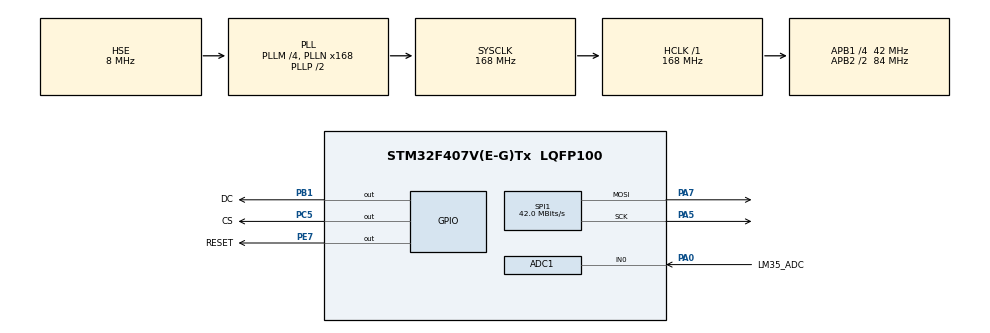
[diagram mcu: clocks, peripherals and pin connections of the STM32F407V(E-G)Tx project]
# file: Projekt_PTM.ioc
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ADC1.Channel-2\#ChannelRegularConversion=ADC_CHANNEL_0
ADC1.ClockPrescaler=ADC_CLOCK_SYNC_PCLK_DIV8
ADC1.ContinuousConvMode=ENABLE
ADC1.DMAContinuousRequests=ENABLE
ADC1.NbrOfConversionFlag=1
ADC1.Rank-2\#ChannelRegularConversion=1
ADC1.SamplingTime-2\#ChannelRegularConversion=ADC_SAMPLETIME_480CYCLES
ADC1.ScanConvMode=ENABLE
ADC1.master=1
Dma.ADC1.0.Direction=DMA_PERIPH_TO_MEMORY
Dma.ADC1.0.FIFOMode=DMA_FIFOMODE_DISABLE
Dma.ADC1.0.Instance=DMA2_Stream0
Dma.ADC1.0.MemDataAlignment=DMA_MDATAALIGN_WORD
Dma.ADC1.0.MemInc=DMA_MINC_ENABLE
Dma.ADC1.0.Mode=DMA_CIRCULAR
Dma.ADC1.0.PeriphDataAlignment=DMA_PDATAALIGN_WORD
Dma.ADC1.0.PeriphInc=DMA_PINC_DISABLE
Dma.ADC1.0.Priority=DMA_PRIORITY_LOW
Dma.Request0=ADC1
Mcu.Family=STM32F4
Mcu.Name=STM32F407V(E-G)Tx
Mcu.Package=LQFP100
NVIC.ADC_IRQn=true\:0\:0\:false\:false\:true\:true\:true
NVIC.DMA2_Stream0_IRQn=true\:0\:0\:false\:false\:true\:false\:true
NVIC.PriorityGroup=NVIC_PRIORITYGROUP_4
PA0-WKUP.GPIO_Label=LM35_ADC
PA0-WKUP.Signal=ADCx_IN0
PA5.Mode=TX_Only_Simplex_Unidirect_Master
PA5.Signal=SPI1_SCK
PA7.Mode=TX_Only_Simplex_Unidirect_Master
PA7.Signal=SPI1_MOSI
PB1.GPIO_Label=DC
PB1.GPIO_ModeDefaultOutputPP=GPIO_MODE_OUTPUT_PP
PB1.GPIO_PuPd=GPIO_NOPULL
PB1.GPIO_Speed=GPIO_SPEED_FREQ_LOW
PB1.PinState=GPIO_PIN_RESET
PB1.Signal=GPIO_Output
PC5.GPIO_Label=CS
PC5.GPIO_ModeDefaultOutputPP=GPIO_MODE_OUTPUT_PP
PC5.GPIO_PuPd=GPIO_NOPULL
PC5.GPIO_Speed=GPIO_SPEED_FREQ_LOW
PC5.PinState=GPIO_PIN_RESET
PC5.Signal=GPIO_Output
PE7.GPIO_Label=RESET
PE7.GPIO_ModeDefaultOutputPP=GPIO_MODE_OUTPUT_PP
PE7.GPIO_PuPd=GPIO_NOPULL
PE7.GPIO_Speed=GPIO_SPEED_FREQ_LOW
PE7.PinState=GPIO_PIN_RESET
PE7.Signal=GPIO_Output
PH0-OSC_IN.Mode=HSE-External-Oscillator
PH0-OSC_IN.Signal=RCC_OSC_IN
PH1-OSC_OUT.Mode=HSE-External-Oscillator
PH1-OSC_OUT.Signal=RCC_OSC_OUT
ProjectManager.HeapSize=0x200
ProjectManager.StackSize=0x400
ProjectManager.TargetToolchain=STM32CubeIDE
RCC.48MHZClocksFreq_Value=84000000
RCC.AHBFreq_Value=168000000
RCC.APB1CLKDivider=RCC_HCLK_DIV4
RCC.APB1Freq_Value=42000000
RCC.APB1TimFreq_Value=84000000
RCC.APB2CLKDivider=RCC_HCLK_DIV2
RCC.APB2Freq_Value=84000000
RCC.APB2TimFreq_Value=168000000
RCC.CortexFreq_Value=168000000
RCC.HCLKFreq_Value=168000000
RCC.HSE_VALUE=8000000
RCC.HSI_VALUE=16000000
RCC.LSE_VALUE=32768
RCC.PLLM=4
RCC.PLLN=168
RCC.PLLSourceVirtual=RCC_PLLSOURCE_HSE
RCC.SYSCLKFreq_VALUE=168000000
RCC.SYSCLKSource=RCC_SYSCLKSOURCE_PLLCLK
RCC.VCOOutputFreq_Value=336000000
SH.ADCx_IN0.0=ADC1_IN0,IN0
SPI1.CLKPhase=SPI_PHASE_2EDGE
SPI1.CLKPolarity=SPI_POLARITY_HIGH
SPI1.CalculateBaudRate=42.0 MBits/s
SPI1.Direction=SPI_DIRECTION_2LINES
SPI1.Mode=SPI_MODE_MASTER
SPI1.VirtualType=VM_MASTER
board=custom

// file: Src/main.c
/* USER CODE BEGIN Header */
/**
  ******************************************************************************
  * @file           : main.c
  * @brief          : Main program body
  ******************************************************************************
  * @attention
  *
  * <h2><center>&copy; Copyright (c) 2020 STMicroelectronics.
  * All rights reserved.</center></h2>
  *
  * This software component is licensed by ST under BSD 3-Clause license,
  * the "License"; You may not use this file except in compliance with the
  * License. You may obtain a copy of the License at:
  *                        opensource.org/licenses/BSD-3-Clause
  *
  ******************************************************************************
  */
/* USER CODE END Header */

#include "main.h"

/* USER CODE BEGIN Includes */
#include "SSD1331.h"
/* USER CODE END Includes */

ADC_HandleTypeDef hadc1;
DMA_HandleTypeDef hdma_adc1;

SPI_HandleTypeDef hspi1;

/* USER CODE BEGIN PV */
uint16_t adc_avg;
uint16_t sum;
float temp=0;
uint16_t temp_buf[9];

/* USER CODE END PV */

void SystemClock_Config(void);
static void MX_GPIO_Init(void);
static void MX_DMA_Init(void);
static void MX_SPI1_Init(void);
static void MX_ADC1_Init(void);
/* USER CODE BEGIN PFP */

void HAL_ADC_ConvCpltCallback(ADC_HandleTypeDef* hadc)
{

	adc_avg=(temp_buf[0]+temp_buf[2]+temp_buf[4]+temp_buf[6]+temp_buf[8])/5;
	temp = ((adc_avg*3*100)/4095);

}

/* USER CODE END PFP */

int main(void)
{

  /* MCU Configuration--------------------------------------------------------*/

  /* Reset of all peripherals, Initializes the Flash interface and the Systick. */
  HAL_Init();

  /* Configure the system clock */
  SystemClock_Config();

  /* Initialize all configured peripherals */
  MX_GPIO_Init();
  MX_DMA_Init();
  MX_SPI1_Init();
  MX_ADC1_Init();
  /* USER CODE BEGIN 2 */

  HAL_ADC_Start_DMA (&hadc1, temp_buf, 5);
  //HAL_Delay(500);
ssd1331_init();
ssd1331_clear_screen(WHITE);

  /* USER CODE END 2 */

  /* Infinite loop */
  /* USER CODE BEGIN WHILE */
   while (1)
  {

	   ssd1331_clear_screen(WHITE);
		  ssd1331_display_num (41,23,temp,2,FONT_1608,BLACK);

		  HAL_Delay(3000);

    /* USER CODE END WHILE */

  }
}

void SystemClock_Config(void)
{
  RCC_OscInitTypeDef RCC_OscInitStruct = {0};
  RCC_ClkInitTypeDef RCC_ClkInitStruct = {0};

  /** Configure the main internal regulator output voltage
  */
  __HAL_RCC_PWR_CLK_ENABLE();
  __HAL_PWR_VOLTAGESCALING_CONFIG(PWR_REGULATOR_VOLTAGE_SCALE1);
  /** Initializes the CPU, AHB and APB busses clocks
  */
  RCC_OscInitStruct.OscillatorType = RCC_OSCILLATORTYPE_HSE;
  RCC_OscInitStruct.HSEState = RCC_HSE_ON;
  RCC_OscInitStruct.PLL.PLLState = RCC_PLL_ON;
  RCC_OscInitStruct.PLL.PLLSource = RCC_PLLSOURCE_HSE;
  RCC_OscInitStruct.PLL.PLLM = 4;
  RCC_OscInitStruct.PLL.PLLN = 168;
  RCC_OscInitStruct.PLL.PLLP = RCC_PLLP_DIV2;
  RCC_OscInitStruct.PLL.PLLQ = 4;
  if (HAL_RCC_OscConfig(&RCC_OscInitStruct) != HAL_OK)
  {
    Error_Handler();
  }
  /** Initializes the CPU, AHB and APB busses clocks
  */
  RCC_ClkInitStruct.ClockType = RCC_CLOCKTYPE_HCLK|RCC_CLOCKTYPE_SYSCLK
                              |RCC_CLOCKTYPE_PCLK1|RCC_CLOCKTYPE_PCLK2;
  RCC_ClkInitStruct.SYSCLKSource = RCC_SYSCLKSOURCE_PLLCLK;
  RCC_ClkInitStruct.AHBCLKDivider = RCC_SYSCLK_DIV1;
  RCC_ClkInitStruct.APB1CLKDivider = RCC_HCLK_DIV4;
  RCC_ClkInitStruct.APB2CLKDivider = RCC_HCLK_DIV2;

  if (HAL_RCC_ClockConfig(&RCC_ClkInitStruct, FLASH_LATENCY_5) != HAL_OK)
  {
    Error_Handler();
  }
}

static void MX_ADC1_Init(void)
{

  ADC_ChannelConfTypeDef sConfig = {0};

  /** Configure the global features of the ADC (Clock, Resolution, Data Alignment and number of conversion)
  */
  hadc1.Instance = ADC1;
  hadc1.Init.ClockPrescaler = ADC_CLOCK_SYNC_PCLK_DIV8;
  hadc1.Init.Resolution = ADC_RESOLUTION_12B;
  hadc1.Init.ScanConvMode = ENABLE;
  hadc1.Init.ContinuousConvMode = ENABLE;
  hadc1.Init.DiscontinuousConvMode = DISABLE;
  hadc1.Init.ExternalTrigConvEdge = ADC_EXTERNALTRIGCONVEDGE_NONE;
  hadc1.Init.ExternalTrigConv = ADC_SOFTWARE_START;
  hadc1.Init.DataAlign = ADC_DATAALIGN_RIGHT;
  hadc1.Init.NbrOfConversion = 1;
  hadc1.Init.DMAContinuousRequests = ENABLE;
  hadc1.Init.EOCSelection = ADC_EOC_SINGLE_CONV;
  if (HAL_ADC_Init(&hadc1) != HAL_OK)
  {
    Error_Handler();
  }
  /** Configure for the selected ADC regular channel its corresponding rank in the sequencer and its sample time.
  */
  sConfig.Channel = ADC_CHANNEL_0;
  sConfig.Rank = 1;
  sConfig.SamplingTime = ADC_SAMPLETIME_480CYCLES;
  if (HAL_ADC_ConfigChannel(&hadc1, &sConfig) != HAL_OK)
  {
    Error_Handler();
  }

}

static void MX_SPI1_Init(void)
{

  /* SPI1 parameter configuration*/
  hspi1.Instance = SPI1;
  hspi1.Init.Mode = SPI_MODE_MASTER;
  hspi1.Init.Direction = SPI_DIRECTION_2LINES;
  hspi1.Init.DataSize = SPI_DATASIZE_8BIT;
  hspi1.Init.CLKPolarity = SPI_POLARITY_HIGH;
  hspi1.Init.CLKPhase = SPI_PHASE_2EDGE;
  hspi1.Init.NSS = SPI_NSS_SOFT;
  hspi1.Init.BaudRatePrescaler = SPI_BAUDRATEPRESCALER_2;
  hspi1.Init.FirstBit = SPI_FIRSTBIT_MSB;
  hspi1.Init.TIMode = SPI_TIMODE_DISABLE;
  hspi1.Init.CRCCalculation = SPI_CRCCALCULATION_DISABLE;
  hspi1.Init.CRCPolynomial = 10;
  if (HAL_SPI_Init(&hspi1) != HAL_OK)
  {
    Error_Handler();
  }

}

static void MX_DMA_Init(void)
{

  /* DMA controller clock enable */
  __HAL_RCC_DMA2_CLK_ENABLE();

  /* DMA interrupt init */
  /* DMA2_Stream0_IRQn interrupt configuration */
  HAL_NVIC_SetPriority(DMA2_Stream0_IRQn, 0, 0);
  HAL_NVIC_EnableIRQ(DMA2_Stream0_IRQn);

}

static void MX_GPIO_Init(void)
{
  GPIO_InitTypeDef GPIO_InitStruct = {0};

  /* GPIO Ports Clock Enable */
  __HAL_RCC_GPIOH_CLK_ENABLE();
  __HAL_RCC_GPIOA_CLK_ENABLE();
  __HAL_RCC_GPIOC_CLK_ENABLE();
  __HAL_RCC_GPIOB_CLK_ENABLE();
  __HAL_RCC_GPIOE_CLK_ENABLE();

  /*Configure GPIO pin Output Level */
  HAL_GPIO_WritePin(CS_GPIO_Port, CS_Pin, GPIO_PIN_RESET);

  /*Configure GPIO pin Output Level */
  HAL_GPIO_WritePin(DC_GPIO_Port, DC_Pin, GPIO_PIN_RESET);

  /*Configure GPIO pin Output Level */
  HAL_GPIO_WritePin(RESET_GPIO_Port, RESET_Pin, GPIO_PIN_RESET);

  /*Configure GPIO pin : CS_Pin */
  GPIO_InitStruct.Pin = CS_Pin;
  GPIO_InitStruct.Mode = GPIO_MODE_OUTPUT_PP;
  GPIO_InitStruct.Pull = GPIO_NOPULL;
  GPIO_InitStruct.Speed = GPIO_SPEED_FREQ_LOW;
  HAL_GPIO_Init(CS_GPIO_Port, &GPIO_InitStruct);

  /*Configure GPIO pin : DC_Pin */
  GPIO_InitStruct.Pin = DC_Pin;
  GPIO_InitStruct.Mode = GPIO_MODE_OUTPUT_PP;
  GPIO_InitStruct.Pull = GPIO_NOPULL;
  GPIO_InitStruct.Speed = GPIO_SPEED_FREQ_LOW;
  HAL_GPIO_Init(DC_GPIO_Port, &GPIO_InitStruct);

  /*Configure GPIO pin : RESET_Pin */
  GPIO_InitStruct.Pin = RESET_Pin;
  GPIO_InitStruct.Mode = GPIO_MODE_OUTPUT_PP;
  GPIO_InitStruct.Pull = GPIO_NOPULL;
  GPIO_InitStruct.Speed = GPIO_SPEED_FREQ_LOW;
  HAL_GPIO_Init(RESET_GPIO_Port, &GPIO_InitStruct);

}

void Error_Handler(void)
{
}

/************************ (C) COPYRIGHT STMicroelectronics *****END OF FILE****/
